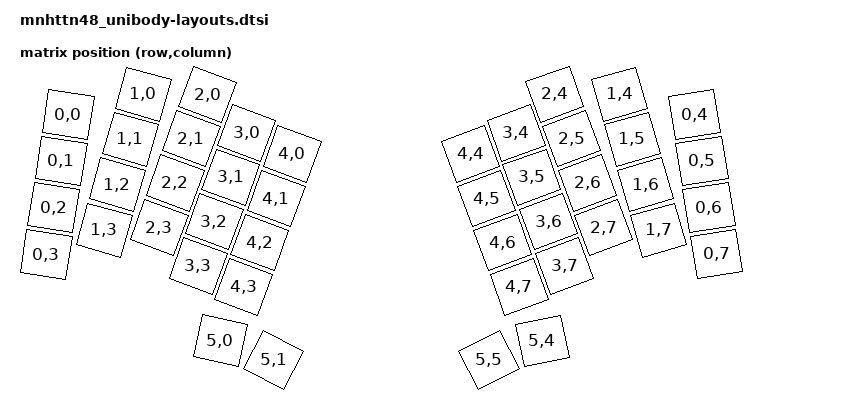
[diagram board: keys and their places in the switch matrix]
/* Generated by tools/gen_zmk.py from board/layout.json and tools/matrix.json, do not edit. */

#include <physical_layouts.dtsi>
#include <dt-bindings/zmk/matrix_transform.h>

/ {
    default_transform: keymap_transform_0 {
        compatible = "zmk,matrix-transform";
        columns = <8>;
        rows = <6>;
        map = <
            RC(0,0) RC(1,0) RC(2,0) RC(3,0) RC(4,0) RC(4,4) RC(3,4) RC(2,4) RC(1,4) RC(0,4)
            RC(0,1) RC(1,1) RC(2,1) RC(3,1) RC(4,1) RC(4,5) RC(3,5) RC(2,5) RC(1,5) RC(0,5)
            RC(0,2) RC(1,2) RC(2,2) RC(3,2) RC(4,2) RC(4,6) RC(3,6) RC(2,6) RC(1,6) RC(0,6)
            RC(0,3) RC(1,3) RC(2,3) RC(3,3) RC(4,3) RC(4,7) RC(3,7) RC(2,7) RC(1,7) RC(0,7)
            RC(5,0) RC(5,1) RC(5,5) RC(5,4)
        >;
    };

    physical_layout0: physical_layout_0 {
        compatible = "zmk,physical-layout";
        display-name = "Default";
        kscan = <&kscan0>;
        transform = <&default_transform>;
        keys  //                   w   h     x     y     rot    rx    ry
            = <&key_physical_attrs 100  94   102    55     900   152   102>
            , <&key_physical_attrs 100  94   252    14    1600   302    61>
            , <&key_physical_attrs 100  94   381    15    2000   431    62>
            , <&key_physical_attrs 100  94   459    92    2000   509   139>
            , <&key_physical_attrs 100  94   550   134    2000   600   181>
            , <&key_physical_attrs 100  94   907   134 (-2000)   957   181>
            , <&key_physical_attrs 100  94   998    92 (-2000)  1048   139>
            , <&key_physical_attrs 100  94  1076    14 (-2000)  1126    62>
            , <&key_physical_attrs 100  94  1205    14 (-1600)  1255    61>
            , <&key_physical_attrs 100  94  1355    55  (-900)  1405   102>
            , <&key_physical_attrs 100  94    88   148     900   138   195>
            , <&key_physical_attrs 100  94   226   104    1600   276   152>
            , <&key_physical_attrs 100  94   348   103    2000   398   150>
            , <&key_physical_attrs 100  94   427   180    2000   477   228>
            , <&key_physical_attrs 100  94   518   223    2000   568   270>
            , <&key_physical_attrs 100  94   939   223 (-2000)   989   270>
            , <&key_physical_attrs 100  94  1030   180 (-2000)  1080   228>
            , <&key_physical_attrs 100  94  1109   103 (-2000)  1159   150>
            , <&key_physical_attrs 100  94  1231   104 (-1600)  1281   152>
            , <&key_physical_attrs 100  94  1370   148  (-900)  1420   195>
            , <&key_physical_attrs 100  94    73   241     900   123   288>
            , <&key_physical_attrs 100  94   200   195    1600   250   242>
            , <&key_physical_attrs 100  94   316   192    2000   366   239>
            , <&key_physical_attrs 100  94   394   269    2000   444   316>
            , <&key_physical_attrs 100  94   485   311    2000   535   359>
            , <&key_physical_attrs 100  94   972   311 (-2000)  1022   359>
            , <&key_physical_attrs 100  94  1063   269 (-2000)  1113   316>
            , <&key_physical_attrs 100  94  1141   192 (-2000)  1191   239>
            , <&key_physical_attrs 100  94  1257   195 (-1600)  1307   242>
            , <&key_physical_attrs 100  94  1384   241  (-900)  1434   288>
            , <&key_physical_attrs 100  94    58   335     900   108   382>
            , <&key_physical_attrs 100  94   174   286    1600   224   333>
            , <&key_physical_attrs 100  94   284   281    2000   334   328>
            , <&key_physical_attrs 100  94   362   358    2000   412   405>
            , <&key_physical_attrs 100  94   453   400    2000   503   447>
            , <&key_physical_attrs 100  94  1004   400 (-2000)  1054   447>
            , <&key_physical_attrs 100  94  1095   358 (-2000)  1145   405>
            , <&key_physical_attrs 100  94  1173   281 (-2000)  1223   328>
            , <&key_physical_attrs 100  94  1283   286 (-1600)  1333   333>
            , <&key_physical_attrs 100  94  1399   334  (-900)  1449   382>
            , <&key_physical_attrs 100  94   406   507    1200   456   555>
            , <&key_physical_attrs 100  94   513   546    2800   563   593>
            , <&key_physical_attrs 100  94   944   546 (-2800)   994   593>
            , <&key_physical_attrs 100  94  1050   508 (-1200)  1100   555>
            ;
    };
};
